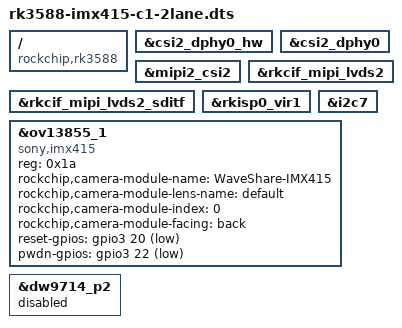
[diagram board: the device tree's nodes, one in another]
/dts-v1/;
/plugin/;


/ {
    compatible = "rockchip,rk3588";

    fragment@0 {
        target = <&csi2_dphy0_hw>;
        __overlay__ {
            status = "okay";
        };
    };

    fragment@1 {
        target = <&csi2_dphy0>;
        __overlay__ {
            status = "okay";
        };
    };

    fragment@2 {
        target = <&mipi2_csi2>;
        __overlay__ {
            status = "okay";
        };
    };

    fragment@3 {
        target = <&rkcif_mipi_lvds2>;
        __overlay__ {
            status = "okay";
        };
    };

    fragment@4 {
        target = <&rkcif_mipi_lvds2_sditf>;
        __overlay__ {
            status = "okay";
        };
    };

    fragment@5 {
        target = <&rkisp0_vir1>;
        __overlay__ {
            status = "okay";
        };
    };

    fragment@6 {
        target = <&i2c7>;
        __overlay__ {
            status = "okay";
        };
    };

    fragment@7 {
        target = <&ov13855_1>;
        __overlay__ {
            status = "okay";
            compatible = "sony,imx415";
            reg = <0x1a>;
            rockchip,camera-module-name = "WaveShare-IMX415";
            rockchip,camera-module-lens-name = "default";
            rockchip,camera-module-index = <0>;
            rockchip,camera-module-facing = "back";
            reset-gpios = <&gpio3 20 1>;
            pwdn-gpios = <&gpio3 22 1>;
            /delete-property/ lens-focus;
        };
    };

    fragment@8 {
        target = <&dw9714_p2>;
        __overlay__ {
            status = "disabled";
        };
    };
};
